# W7500x register map
Vendor: WIZnet; File version: 1.0.0
The IOP (Internet Offload Processor) W7500P is the one-chip solution which integrates an ARM Cortex-M0, 128KB Flash and hardwired TCP/IP core & PHY for various embedded application platform especially requiring ‘Internet of things’. The TCP/IP core is a market-proven hardwired TCP/IP stack with an integrated Ethernet MAC. The Hardwired TCP/IP stack supports the TCP, UDP, IPv4, ICMP, ARP, IGMP and PPPoE which has been used in various applications for years. W7500P suits best for users who need Internet connectivity for application.
CPU: CM0 r0p0, little endian, no MPU, no FPU, 2 interrupt priority bits
Registers are 32-bit, read-write, reset 0x0 unless marked. A register's access mark holds for its fields unless they carry their own. Offsets are from the block's base; lines under a group give offsets from that group; [hi:lo] are bit positions; {n}, {i} and the like mark numbered series; 'fields as' and 'values as' point back to an identical list; <NAME> marks a mode.

## Memory map
0x40000000 WDT size 0xC04
0x40001000 DUALTIMER0_0 size 0x84
0x40001020 DUALTIMER0_1 size 0x84
0x40002000 DUALTIMER1_0 size 0x84
0x40002020 DUALTIMER1_1 size 0x84
{0x40005000+0x100*n} PWM{n} size 0x40 (n=0..7)
0x40005800 PWM size 0xC
0x40006000 UART2 size 0x14
0x40007000 RNG size 0x18
0x4000A000 SSP0 size 0x28
0x4000B000 SSP1 size 0x28
0x4000C000 UART0 size 0x4C
0x4000D000 UART1 size 0x4C
0x4000E000 RTC size 0x50
0x4001F000 SYSCFG size 0x14
0x41000000 ADC size 0x20
0x41001000 CRG size 0x174
0x41002000 AFC_PA
0x41002040 AFC_PB
0x41002080 AFC_PC
0x410020C0 AFC_PD
0x41002200 EXTI_PA
0x41002240 EXTI_PB
0x41002280 EXTI_PC
0x410022C0 EXTI_PD
0x41003000 PADCON_PA
0x41003040 PADCON_PB
0x41003080 PADCON_PC
0x410030C0 PADCON_PD
0x41004000 DMA size 0x50
0x42000000 GPIOA size 0xC00
0x43000000 GPIOB size 0xC00
0x44000000 GPIOC size 0xC00
0x45000000 GPIOD size 0xC00

## Interrupts
0 SSP0 — SSP 0 Interrupt
1 SSP1 — SSP 1 Interrupt
2 UART0 — UART 0 Interrupt
3 UART1 — UART 1 Interrupt
4 UART2 — UART 2 Interrupt
7 PORT0 (GPIOA) — Port 0 combined Interrupt
8 PORT1 (GPIOB) — Port 1 combined Interrupt
9 PORT2 (GPIOC) — Port 2 combined Interrupt
10 PORT3 (GPIOD) — Port 3 combined Interrupt
11 DMA — DMA combined Interrupt
12 DUALTIMER0 (DUALTIMER0_0, DUALTIMER0_1) — Dual Timer 0 Interrupt
13 DUALTIMER1 (DUALTIMER1_0, DUALTIMER1_1) — Dual Timer 1 Interrupt
{n+14} PWM{n} (n=0..7) — PWM {n} Interrupt
22 RTC — RTC Interrupt
23 ADC — ADC Interrupt

## WDT
Base 0x40000000
0x00 LOAD — Watchdog timer Load register
  [31:0] WLR — Watchdog timer Load
0x04 VALUE ro — Watchdog timer Value register
  [31:0] WVR — Watchdog timer Value
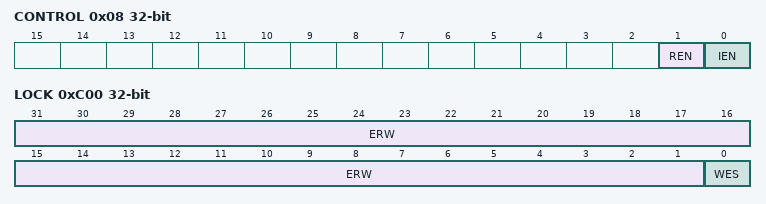
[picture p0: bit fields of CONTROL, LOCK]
0x08 CONTROL — Watchdog timer Control register
  [1] REN — Reset Request Enable
    0=Disable; 1=Enable
  [0] IEN — Interrupt Enable
    0=Disable; 1=Enable
0x0C INTCLR wo — Watchdog timer Clear Interrupt register
  [0] WIC — Watchdog timer Interrupt Clear
    1=Clear
0x10 RIS ro — Watchdog timer Raw Interrupt Status register
  [0] RIS — Watchdog timer Raw Interrupt Status
0x14 MIS ro — Watchdog timer Masked Interrupt Status register
  [0] MIS — Watchdog timer Masked Interrupt Status
0xC00 LOCK — Watchdog timer Lock register
  [31:1] ERW — ERW[31:1] bits (Enable Register Writes)
    0=Lock; 0x1ACCE551=UnLock
  [0] WES — Register Write Enable status
    0=NotLocked; 1=Locked

## DUALTIMER0_0
Base 0x40001000
Same registers: DUALTIMER0_1 0x40001020, DUALTIMER1_0 0x40002000, DUALTIMER1_1 0x40002020
0x00 LOAD — Timer Load register
  [31:0] TLR — Timer Load
0x04 VALUE ro — Timer Counter Current Value register
  [31:0] TVR — Timer Value
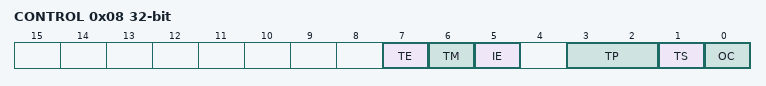
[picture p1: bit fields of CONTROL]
0x08 CONTROL — Timer Control register
  [7] TE — Timer Enable
  [6] TM — Timer Mode
  [5] IE — Interrupt Enable
  [3:2] TP — Timer Prescale
  [1] TS — Timer Size
  [0] OC — One-shot Count
0x0C INTCLR wo — Timer Interrupt Clear register
  [0] TIC — Interrupt Clear
0x10 RIS ro — Timer Raw Interrupt Status register
  [0] RIS — Raw Interrupt Status flag
0x14 MIS ro — Timer Masked Interrupt Status register
  [0] MIS — Masked Interrupt Status flag
0x18 BGLOAD — Background Load register
  [31:0] BGL — Background Load
0x80 CE reset not defined — Clock enable register
